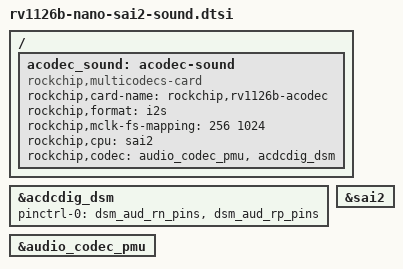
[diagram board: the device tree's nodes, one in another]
// SPDX-License-Identifier: (GPL-2.0+ OR MIT)
/*
 * Copyright (c) 2025 Guangzhou EASY EAI Technology Co., Ltd.
 */

/ {
	acodec_sound: acodec-sound {
		status = "okay";
		compatible = "rockchip,multicodecs-card";
		rockchip,card-name = "rockchip,rv1126b-acodec";
		rockchip,format = "i2s";
		rockchip,mclk-fs-mapping = <256 1024>;
		rockchip,cpu = <&sai2>;
		rockchip,codec = <&audio_codec_pmu>, <&acdcdig_dsm>;
	};
};

&acdcdig_dsm {
	status = "okay";
	//pa-ctl-gpios = <&gpio0 RK_PA4 GPIO_ACTIVE_HIGH>;
	pinctrl-0 = <&dsm_aud_rn_pins &dsm_aud_rp_pins>;
};

&audio_codec_pmu {
	status = "okay";
};

&sai2 {
	status = "okay";
	/delete-property/ pinctrl-names;
	/delete-property/ pinctrl-0;
};
